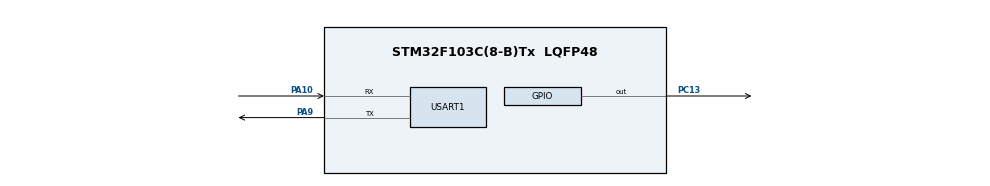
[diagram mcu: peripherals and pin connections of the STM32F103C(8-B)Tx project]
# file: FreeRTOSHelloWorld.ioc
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FREERTOS.BinarySemaphores01=myBinarySem01,Dynamic,NULL
FREERTOS.Tasks01=HelloWorld01,24,128,helloWorld01Task,Default,NULL,Dynamic,NULL,NULL;HelloWorld02,8,128,helloWorld02Task,Default,NULL,Dynamic,NULL,NULL;HelloWorld03,40,128,helloWorld03,Default,NULL,Dynamic,NULL,NULL
Mcu.Family=STM32F1
Mcu.Name=STM32F103C(8-B)Tx
Mcu.Package=LQFP48
NVIC.PriorityGroup=NVIC_PRIORITYGROUP_4
NVIC.TIM4_IRQn=true\:0\:0\:false\:false\:true\:false\:false\:true
NVIC.TimeBase=TIM4_IRQn
NVIC.TimeBaseIP=TIM4
PA10.Mode=Asynchronous
PA10.Signal=USART1_RX
PA9.Mode=Asynchronous
PA9.Signal=USART1_TX
PC13-TAMPER-RTC.Signal=GPIO_Output
ProjectManager.HeapSize=0x200
ProjectManager.StackSize=0x400
ProjectManager.TargetToolchain=STM32CubeIDE
RCC.APB1Freq_Value=8000000
RCC.APB2Freq_Value=8000000
USART1.VirtualMode=VM_ASYNC
VP_FREERTOS_VS_CMSIS_V2.Mode=CMSIS_V2
VP_SYS_VS_ND.Mode=No_Debug
VP_SYS_VS_tim4.Mode=TIM4
board=custom

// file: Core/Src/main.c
/* USER CODE BEGIN Header */
/**
 ******************************************************************************
 * @file           : main.c
 * @brief          : Main program body
 ******************************************************************************
 * @attention
 *
 * <h2><center>&copy; Copyright (c) 2021 STMicroelectronics.
 * All rights reserved.</center></h2>
 *
 * This software component is licensed by ST under BSD 3-Clause license,
 * the "License"; You may not use this file except in compliance with the
 * License. You may obtain a copy of the License at:
 *                        opensource.org/licenses/BSD-3-Clause
 *
 ******************************************************************************
 */
/* USER CODE END Header */
#include "main.h"
#include "cmsis_os.h"

UART_HandleTypeDef huart1;

/* Definitions for HelloWorld01 */
osThreadId_t HelloWorld01Handle;
const osThreadAttr_t HelloWorld01_attributes = {
  .name = "HelloWorld01",
  .priority = (osPriority_t) osPriorityNormal,
  .stack_size = 128 * 4
};
/* Definitions for HelloWorld02 */
osThreadId_t HelloWorld02Handle;
const osThreadAttr_t HelloWorld02_attributes = {
  .name = "HelloWorld02",
  .priority = (osPriority_t) osPriorityLow,
  .stack_size = 128 * 4
};
/* Definitions for HelloWorld03 */
osThreadId_t HelloWorld03Handle;
const osThreadAttr_t HelloWorld03_attributes = {
  .name = "HelloWorld03",
  .priority = (osPriority_t) osPriorityHigh,
  .stack_size = 128 * 4
};
/* Definitions for myBinarySem01 */
osSemaphoreId_t myBinarySem01Handle;
const osSemaphoreAttr_t myBinarySem01_attributes = {
  .name = "myBinarySem01"
};

void SystemClock_Config(void);
static void MX_GPIO_Init(void);
static void MX_USART1_UART_Init(void);
void helloWorld01Task(void *argument);
void helloWorld02Task(void *argument);
void helloWorld03(void *argument);

int main(void)
{

  /* MCU Configuration--------------------------------------------------------*/

  /* Reset of all peripherals, Initializes the Flash interface and the Systick. */
  HAL_Init();

  /* Configure the system clock */
  SystemClock_Config();

  /* Initialize all configured peripherals */
  MX_GPIO_Init();
  MX_USART1_UART_Init();

  /* Init scheduler */
  osKernelInitialize();

  /* Create the semaphores(s) */
  /* creation of myBinarySem01 */
  myBinarySem01Handle = osSemaphoreNew(1, 1, &myBinarySem01_attributes);

  /* Create the thread(s) */
  /* creation of HelloWorld01 */
  HelloWorld01Handle = osThreadNew(helloWorld01Task, NULL, &HelloWorld01_attributes);

  /* creation of HelloWorld02 */
  HelloWorld02Handle = osThreadNew(helloWorld02Task, NULL, &HelloWorld02_attributes);

  /* creation of HelloWorld03 */
  HelloWorld03Handle = osThreadNew(helloWorld03, NULL, &HelloWorld03_attributes);

  /* Start scheduler */
  osKernelStart();

  /* We should never get here as control is now taken by the scheduler */
  /* Infinite loop */
	while (1) {

	}
}

void SystemClock_Config(void)
{
  RCC_OscInitTypeDef RCC_OscInitStruct = {0};
  RCC_ClkInitTypeDef RCC_ClkInitStruct = {0};

  /** Initializes the RCC Oscillators according to the specified parameters
  * in the RCC_OscInitTypeDef structure.
  */
  RCC_OscInitStruct.OscillatorType = RCC_OSCILLATORTYPE_HSI;
  RCC_OscInitStruct.HSIState = RCC_HSI_ON;
  RCC_OscInitStruct.HSICalibrationValue = RCC_HSICALIBRATION_DEFAULT;
  RCC_OscInitStruct.PLL.PLLState = RCC_PLL_NONE;
  if (HAL_RCC_OscConfig(&RCC_OscInitStruct) != HAL_OK)
  {
    Error_Handler();
  }
  /** Initializes the CPU, AHB and APB buses clocks
  */
  RCC_ClkInitStruct.ClockType = RCC_CLOCKTYPE_HCLK|RCC_CLOCKTYPE_SYSCLK
                              |RCC_CLOCKTYPE_PCLK1|RCC_CLOCKTYPE_PCLK2;
  RCC_ClkInitStruct.SYSCLKSource = RCC_SYSCLKSOURCE_HSI;
  RCC_ClkInitStruct.AHBCLKDivider = RCC_SYSCLK_DIV1;
  RCC_ClkInitStruct.APB1CLKDivider = RCC_HCLK_DIV1;
  RCC_ClkInitStruct.APB2CLKDivider = RCC_HCLK_DIV1;

  if (HAL_RCC_ClockConfig(&RCC_ClkInitStruct, FLASH_LATENCY_0) != HAL_OK)
  {
    Error_Handler();
  }
}

static void MX_USART1_UART_Init(void)
{

  huart1.Instance = USART1;
  huart1.Init.BaudRate = 115200;
  huart1.Init.WordLength = UART_WORDLENGTH_8B;
  huart1.Init.StopBits = UART_STOPBITS_1;
  huart1.Init.Parity = UART_PARITY_NONE;
  huart1.Init.Mode = UART_MODE_TX_RX;
  huart1.Init.HwFlowCtl = UART_HWCONTROL_NONE;
  huart1.Init.OverSampling = UART_OVERSAMPLING_16;
  if (HAL_UART_Init(&huart1) != HAL_OK)
  {
    Error_Handler();
  }

}

static void MX_GPIO_Init(void)
{
  GPIO_InitTypeDef GPIO_InitStruct = {0};

  /* GPIO Ports Clock Enable */
  __HAL_RCC_GPIOC_CLK_ENABLE();
  __HAL_RCC_GPIOA_CLK_ENABLE();

  /*Configure GPIO pin Output Level */
  HAL_GPIO_WritePin(GPIOC, GPIO_PIN_13, GPIO_PIN_RESET);

  /*Configure GPIO pin : PC13 */
  GPIO_InitStruct.Pin = GPIO_PIN_13;
  GPIO_InitStruct.Mode = GPIO_MODE_OUTPUT_PP;
  GPIO_InitStruct.Pull = GPIO_NOPULL;
  GPIO_InitStruct.Speed = GPIO_SPEED_FREQ_LOW;
  HAL_GPIO_Init(GPIOC, &GPIO_InitStruct);

}

void helloWorld01Task(void *argument)
{
  /* USER CODE BEGIN 5 */
	/* Infinite loop */
	for (;;) {
		char *str1 = "Entered MediumTask\r\n";
		HAL_UART_Transmit(&huart1, (uint8_t*) str1, strlen(str1), 100);

		char *str2 = "Leaving MediumTask\r\n\r\n";
		HAL_UART_Transmit(&huart1, (uint8_t*) str2, strlen(str2), 100);
		osDelay(500);
	}

	osThreadTerminate(NULL);
  /* USER CODE END 5 */
}

void helloWorld02Task(void *argument)
{
  /* USER CODE BEGIN helloWorld02Task */
	/* Infinite loop */
	for (;;) {
		char *str1 = "Entered LOWTask and waiting for semaphore\r\n";
		HAL_UART_Transmit(&huart1, (uint8_t*) str1, strlen(str1), 100);

		osSemaphoreAcquire(myBinarySem01Handle, osWaitForever);
		char *str3 = "Semaphore acquired by LOW Task\r\n";
		HAL_UART_Transmit(&huart1, (uint8_t*) str3, strlen(str3), 100);

//		while (HAL_GPIO_ReadPin(GPIOC, GPIO_PIN_13))
//			;  // wait till the pin go low

		HAL_GPIO_TogglePin(GPIOC, GPIO_PIN_13);

		char *str2 = "Leaving LOWTask and releasing Semaphore\r\n\r\n";
		HAL_UART_Transmit(&huart1, (uint8_t*) str2, strlen(str2), 100);

		osSemaphoreRelease(myBinarySem01Handle);
		osDelay(500);
	}

	osThreadTerminate(NULL);
  /* USER CODE END helloWorld02Task */
}

void helloWorld03(void *argument)
{
  /* USER CODE BEGIN helloWorld03 */
	/* Infinite loop */
	for (;;) {
		char *str1 = "Entered HighTask and waiting for Semaphore\r\n";
		HAL_UART_Transmit(&huart1, (uint8_t*) str1, strlen(str1), 100);

		osSemaphoreAcquire(myBinarySem01Handle, osWaitForever);

		char *str3 = "Semaphore acquired by HIGH Task\r\n";
		HAL_UART_Transmit(&huart1, (uint8_t*) str3, strlen(str3), 100);

		char *str2 = "Leaving HighTask and releasing Semaphore\r\n\r\n";
		HAL_UART_Transmit(&huart1, (uint8_t*) str2, strlen(str2), 100);

		osSemaphoreRelease(myBinarySem01Handle);
		osDelay(500);
	}

	osThreadTerminate(NULL);
  /* USER CODE END helloWorld03 */
}

 /**
  * @brief  Period elapsed callback in non blocking mode
  * @note   This function is called  when TIM4 interrupt took place, inside
  * HAL_TIM_IRQHandler(). It makes a direct call to HAL_IncTick() to increment
  * a global variable "uwTick" used as application time base.
  * @param  htim : TIM handle
  * @retval None
  */
void HAL_TIM_PeriodElapsedCallback(TIM_HandleTypeDef *htim)
{
  if (htim->Instance == TIM4) {
    HAL_IncTick();
  }
}

void Error_Handler(void)
{
	__disable_irq();
	while (1) {
	}
}

/************************ (C) COPYRIGHT STMicroelectronics *****END OF FILE****/
